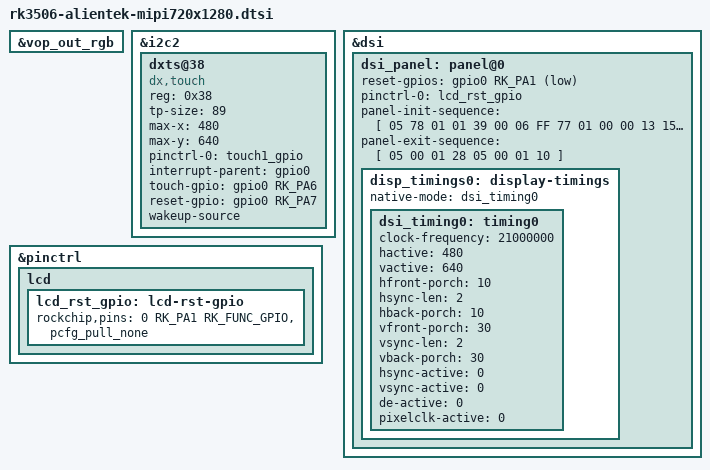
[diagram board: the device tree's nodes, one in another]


#define D310T9362V1     0
#define D350T1013V1     0
#define D240C2501V1     1	
#define D280C2518V0     0	
#define D300T9307V1     0
#define D200C2409V0     0
#define D500C9366V1     0 
#define D395C930UV0     0
#define D500C930SV0     0   //5" g5 7201280
#define D050C2523V0     0   //5" g6 7201280
#define D050C2521V0     0   //5" 1024600
#define D070C2529V0     0    //7" 1024600
#define D060C2522V0     0   //6" 720 1440
#define D320C2403V1     0
#define D200N2415V0     0









&vop_out_rgb {
        /delete-property/ remote-endpoint;
};



&i2c2 {





	dxts@38 {

               compatible = "dx,touch";
               reg = <0x38>;
               tp-size = <89>;
               max-x = <480>;
               max-y = <640>;
               pinctrl-names = "default";
               pinctrl-0 = <&touch1_gpio>;
	       interrupt-parent = <&gpio0>;
               touch-gpio = <&gpio0 RK_PA6 IRQ_TYPE_LEVEL_LOW>;
               reset-gpio = <&gpio0 RK_PA7 GPIO_ACTIVE_HIGH>;
                wakeup-source;
                //touchscreen-inverted-x;
                //touchscreen-swapped-x-y;
                status = "okay";
        };

	/delete-node/ gt1x;
};






// ************************************************************************************************************************************************
// 3.1寸大显 D310T9362V1
// 480x800
// ************************************************************************************************************************************************
	#if(D310T9362V1)
	

&dsi {
	status = "okay";
//	rockchip,lane-rate = <1000>;
        dsi_panel: panel@0 {
        	reset-gpios = <&gpio0 RK_PA1 GPIO_ACTIVE_LOW>;
                pinctrl-names = "default";
                pinctrl-0 = <&lcd_rst_gpio>;

		panel-init-sequence = [
			// init code
			05 78 01 01
			05 78 01 11
			39 00 06 FF 77 01 00 00 11
			15 00 02 D1 11
			15 00 02 55 B0 // 80 90 b0
			39 00 06 FF 77 01 00 00 10
			39 00 03 C0 63 00
			39 00 03 C1 09 02
			39 00 03 C2 37 08
			15 00 02 C7 00 // x-dir rotate 0:0x00,rotate 180:0x04
			15 00 02 CC 38
			39 00 11 B0 00 11 19 0C 10 06 07 0A 09 22 04 10 0E 28 30 1C
			39 00 11 B1 00 12 19 0D 10 04 06 07 08 23 04 12 11 28 30 1C
			39 00 06 FF 77 01 00 00 11 // enable  bk fun of  command 2  BK1
			15 00 02 B0 4D
			15 00 02 B1 60 // 0x56  0x4a  0x5b
			15 00 02 B2 07
			15 00 02 B3 80
			15 00 02 B5 47
			15 00 02 B7 8A
			15 00 02 B8 21
			15 00 02 C1 78
			15 00 02 C2 78
			15 64 02 D0 88
			39 00 04 E0 00 00 02
			39 00 0C E1 01 A0 03 A0 02 A0 04 A0 00 44 44
			39 00 0D E2 00 00 00 00 00 00 00 00 00 00 00 00
			39 00 05 E3 00 00 33 33
			39 00 03 E4 44 44
			39 00 11 E5 01 26 A0 A0 03 28 A0 A0 05 2A A0 A0 07 2C A0 A0
			39 00 05 E6 00 00 33 33
			39 00 03 E7 44 44
			39 00 11 E8 02 26 A0 A0 04 28 A0 A0 06 2A A0 A0 08 2C A0 A0
			39 00 08 EB 00 01 E4 E4 44 00 40
			39 00 11 ED FF F7 65 4F 0B A1 CF FF FF FC 1A B0 F4 56 7F FF
		  //  39 00 06 FF 77 01 00 00 12  //BIST
          //  15 00 02 D1 81 
		  //  15 00 02 D2 07
			39 00 06 FF 77 01 00 00 00
			15 00 02 36 00 //U&D  Y-DIR rotate 0:0x00,rotate 180:0x10
			05 78 01 11           
			05 14 01 29		
		];

		panel-exit-sequence = [
			05 00 01 28
			05 00 01 10
		];

                disp_timings0: display-timings {
                        native-mode = <&dsi_timing0>;
                        dsi_timing0: timing0 {
 				clock-frequency = <27000000>;
				hactive = <480>;   	
				vactive = <800>;   	 
				hfront-porch = <32>;  
				hsync-len = <4>;   	 
				hback-porch = <32>;  
				vfront-porch = <9>;  
				vsync-len = <4>;     
				vback-porch = <3>;   
				hsync-active = <0>;
				vsync-active = <0>;
				de-active = <0>;
				pixelclk-active = <0>;
                        };
                };

        };
};
#endif






// ************************************************************************************************************************************************
// 3.5寸大显 D350T1013V1
// 480x800
// ************************************************************************************************************************************************
	#if(D350T1013V1)
	
&dsi {
	status = "okay";
//	rockchip,lane-rate = <1000>;
        dsi_panel: panel@0 {
        	reset-gpios = <&gpio0 RK_PA1 GPIO_ACTIVE_LOW>;
                pinctrl-names = "default";
                pinctrl-0 = <&lcd_rst_gpio>;

		panel-init-sequence = [
			// init code
			05 78 01 01
			39 00 06 FF 77 01 00 00 13
			15 00 02 EF 08
			39 00 06 FF 77 01 00 00 10
			39 00 03 C0 63 00
			39 00 03 C1 10 02
			39 00 03 C2 31 02
			15 00 02 CC 10
			39 00 11 B0 C0 0C 92 0C 10 05 02 0D 07 21 04 53 11 6A 32 1F
			39 00 11 B1 C0 87 CF 0C 10 06 00 03 08 1D 06 54 12 E6 EC 0F
			39 00 06 FF 77 01 00 00 11 //  BK1
			15 00 02 B0 5D
			15 00 02 B1 72 // VCOM
			15 00 02 B2 82
			15 00 02 B3 80
			15 00 02 B5 42
			15 00 02 B7 85
			15 00 02 B8 20
			15 00 02 C1 78
			15 00 02 C2 78
			15 64 02 D0 88
			39 00 04 E0 00 00 02
			39 00 0C E1 04 A0 06 A0 05 A0 07 A0 00 44 44
			39 00 0D E2 00 00 33 33 01 A0 00 00 01 A0 00 00
			39 00 05 E3 00 00 33 33
			39 00 03 E4 44 44
			39 00 11 E5 0C 30 A0 A0 0E 32 A0 A0 08 2C A0 A0 0A 2E A0 A0
			39 00 05 E6 00 00 33 33
			39 00 03 E7 44 44
			39 00 11 E8 0D 31 A0 A0 0F 33 A0 A0 09 2D A0 A0 0B 2F A0 A0
			39 00 08 EB 00 01 E4 E4 44 88 00
			39 00 11 ED FF F5 47 6F 0B A1 A2 BF FB 2A 1A B0 F6 74 5F FF
			39 00 07 FF 08 08 08 40 3F 64
			39 00 06 FF 77 01 00 00 13
			39 00 03 E8 00 0E
			39 00 06 FF 77 01 00 00 00
			05 78 01 11    
			39 00 06 FF 77 01 00 00 13
			39 14 03 E8 00 0C   
			39 00 03 E8 00 00  
          //  39 00 06 FF 77 01 00 00 12  //BIST
          //  15 00 D1 81 
		  //  15 00 D2 07
			39 00 06 FF 77 01 00 00 00 
			05 14 01 29		
		];

		panel-exit-sequence = [
			05 00 01 28
			05 00 01 10
		];

                disp_timings0: display-timings {
                        native-mode = <&dsi_timing0>;
                        dsi_timing0: timing0 {
 				clock-frequency = <27000000>;
				hactive = <480>;   	
				vactive = <800>;   	 
				hfront-porch = <32>;  
				hsync-len = <4>;   	 
				hback-porch = <32>;  
				vfront-porch = <9>;  
				vsync-len = <4>;     
				vback-porch = <3>;   
				hsync-active = <0>;
				vsync-active = <0>;
				de-active = <0>;
				pixelclk-active = <0>;
                        };
                };

        };
};
#endif


// ************************************************************************************************************************************************
// 2.4寸大显 D240C2501V1
// 480x640
// ************************************************************************************************************************************************
 
	#if(D240C2501V1)
&dsi {
	status = "okay";
//	rockchip,lane-rate = <1000>;
        dsi_panel: panel@0 {
        	reset-gpios = <&gpio0 RK_PA1 GPIO_ACTIVE_LOW>;
                pinctrl-names = "default";
                pinctrl-0 = <&lcd_rst_gpio>;

		panel-init-sequence = [
			// init code
			05 78 01 01
			39 00 06 FF 77 01 00 00 13
			15 00 02 EF 08
			39 00 06 FF 77 01 00 00 10
			39 00 03 C0 4F 00
			39 00 03 C1 10 0C
			39 00 03 C2 37 04
			15 00 02 C7 00 // x-dir rotate 0:0x00,rotate 180:0x04
			15 00 02 CC 10
			39 00 11 B0 00 0B 13 0D 10 07 02 08 07 1F 04 11 0F 28 2F 1F
			39 00 11 B1 00 0C 13 0C 10 05 02 08 08 1E 05 13 11 27 30 1F
			39 00 06 FF 77 01 00 00 11 // enable  bk fun of  command 2  BK1
			15 00 02 B0 4A //VOP
			15 00 02 B1 4A // VCOM
			15 00 02 B2 87 //VGH
			15 00 02 B3 80
			15 00 02 B5 45 //VGL
			15 00 02 B7 85
			15 00 02 B8 20
			15 00 02 C1 78
			15 00 02 C2 78
			15 64 02 D0 88
			39 00 04 E0 00 00 02
			39 00 0C E1 04 B0 06 B0 05 B0 05 B0 00 44 44
			39 00 0D E2 20 20 44 44 96 A0 00 00 96 A0 00 00
			39 00 05 E3 00 00 22 22
			39 00 03 E4 44 44
			39 00 11 E5 0C 90 B0 A0 0E 92 B0 A0 08 8C B0 A0 0A 8E B0 A0
			39 00 05 E6 00 00 22 22
			39 00 03 E7 44 44
			39 00 11 E8 0D 91 B0 A0 0F 93 B0 A0 09 8D B0 A0 0B 8F B0 A0
			39 00 03 E9 36 44
			39 00 08 EB 00 00 E4 E4 44 00 40
			39 00 11 ED C1 A2 BF 0F 67 45 FF FF FF FF 54 76 F0 FB 2A 1C
			39 00 07 EF 10 0D 04 08 3F 1F
			39 00 06 FF 77 01 00 00 13
		    39 00 03 E8 00 0E
			39 00 06 FF 77 01 00 00 00
	        05 78 01 11
			39 00 06 FF 77 01 00 00 13
		    39 14 03 E8 00 0C
		    39 14 03 E8 00 00
			39 00 06 FF 77 01 00 00 00
			15 00 02 36 00 //U&D  Y-DIR rotate 0:0x00,rotate 180:0x10          
			05 14 01 29		
		];

		panel-exit-sequence = [
			05 00 01 28
			05 00 01 10
		];

                disp_timings0: display-timings {
                        native-mode = <&dsi_timing0>;
                        dsi_timing0: timing0 {
				clock-frequency = <21000000>;
				hactive = <480>;   	
				vactive = <640>;   	 
				hfront-porch = <10>;  
				hsync-len = <2>;   	 
				hback-porch = <10>;  
				vfront-porch = <30>;  
				vsync-len = <2>;     
				vback-porch = <30>;   
				hsync-active = <0>;
				vsync-active = <0>;
				de-active = <0>;
				pixelclk-active = <0>;
                        };
                };

        };
};
#endif



// ************************************************************************************************************************************************
// 2.8寸大显 D280C2518V0
// 480x640
// ************************************************************************************************************************************************
 	#if(D280C2518V0)
	
&dsi {
	status = "okay";
//	rockchip,lane-rate = <1000>;
        dsi_panel: panel@0 {
        	reset-gpios = <&gpio0 RK_PA1 GPIO_ACTIVE_LOW>;
                pinctrl-names = "default";
                pinctrl-0 = <&lcd_rst_gpio>;

		panel-init-sequence = [
			// init code
39 00 06 FF 77 01 00 00 13
15 00 02 EF 08
39 00 06 FF 77 01 00 00 10
39 00 03 C0 4F 00
39 00 03 C1 10 02
39 00 03 C2 00 02
15 00 02 CC 10
39 00 11 B0 00 10 17 0D 11 06 05 08 07 1F 04 11 0E 29 30 1F
39 00 11 B1 00 0D 14 0E 11 06 04 08 08 20 05 13 13 26 30 1F
39 00 06 FF 77 01 00 00 11
15 00 02 B0 69
15 00 02 B1 71
15 00 02 B2 82
15 00 02 B3 80
15 00 02 B5 42
15 00 02 B7 85
15 00 02 B8 20
15 00 02 C0 09
15 00 02 C1 78
15 00 02 C2 78
15 00 02 D0 88
15 00 02 EE 42
39 00 04 E0 00 00 02
39 00 0c E1 04 A0 06 A0 05 A0 07 A0 00 44 44
39 00 0d E2 00 00 00 00 00 00 00 00 00 00 00 00
39 00 05 E3 00 00 22 22
39 00 03 E4 44 44
39 00 11 E5 0c 90 A0 A0 0E 92 A0 A0 08 8C A0 A0 0A 8E A0 A0
39 00 05 E6 00 00 22 22
39 00 03 E7 44 44
39 00 11 E8 0D 91 A0 A0 0F 93 A0 A0 09 8D A0 A0 0B 8F A0 A0
//39 00 03 E9 36 00
39 00 08 EB 00 00 E4 E4 44 00 40
39 00 11 ED FF F5 47 6F 0B A1 AB FF FF BA 1A B0 F6 74 5F FF
39 00 07 EF 08 08 08 40 3F 64
39 00 06 FF 77 01 00 00 00
39 00 06 FF 77 01 00 00 13
39 00 03 E6 16 7C
39 00 03 E8 00 0E
39 00 06 FF 77 01 00 00 00
15 78 02 11 00
39 00 06 FF 77 01 00 00 13
39 14 03 E8 00 0C
39 00 03 E8 00 00
//bist
//39 00 06 FF 77 01 00 00 12
//15 00 02 D1 81
//15 00 02 D2 07
39 00 06 FF 77 01 00 00 00
15 00 02 3A 70
05 14 01 29
		];

		panel-exit-sequence = [
			05 00 01 28
			05 00 01 10
		];

                disp_timings0: display-timings {
                        native-mode = <&dsi_timing0>;
                        dsi_timing0: timing0 {
				clock-frequency = <21000000>;
				hactive = <480>;   	
				vactive = <640>;   	 
				hfront-porch = <10>;  
				hsync-len = <2>;   	 
				hback-porch = <10>;  
				vfront-porch = <30>;  
				vsync-len = <2>;     
				vback-porch = <30>;   
				hsync-active = <0>;
				vsync-active = <0>;
				de-active = <0>;
				pixelclk-active = <0>;
                        };
                };

        };
};
#endif




// ************************************************************************************************************************************************
// 3.0寸大显 D300T9307V1
// 480x854
// ************************************************************************************************************************************************
	#if(D300T9307V1)
	
&dsi {
	status = "okay";
        dsi_panel: panel@0 {
        	reset-gpios = <&gpio0 RK_PA1 GPIO_ACTIVE_LOW>;
                pinctrl-names = "default";
                pinctrl-0 = <&lcd_rst_gpio>;

		panel-init-sequence = [
			// init code
			15 00 02 B0 5D
			15 00 02 B1 72 // VCOM
			15 00 02 B2 82
			15 00 02 B3 80
			15 00 02 B5 42
			15 00 02 B7 85
		05 78 01 01
			39 00 06 FF 77 01 00 00 13
			15 00 02 EF 08
			39 00 06 FF 77 01 00 00 10
			39 00 03 C0 E9 03
			39 00 03 C1 12 0C
			39 00 03 C2 27 0A
			15 00 02 CC 10
			39 00 11 B0 00 23 2A 0A 0E 03 12 06 06 2A 00 10 0F 2D 34 1F
			39 00 11 B1 00 24 2B 0F 12 07 15 0A 0A 2B 08 13 10 2D 33 1F
			39 00 06 FF 77 01 00 00 11 // enable  bk fun of  command 2  BK1
			15 00 02 B0 5D
			15 00 02 B1 74 // VCOM
			15 00 02 B2 84
			15 00 02 B3 80
			15 00 02 B5 45
			15 00 02 B7 85
			15 00 02 B8 33
			15 00 02 C1 78
			15 00 02 C2 78
			15 64 02 D0 88
			39 00 04 E0 00 00 02
            39 00 0C E1 06 A0 08 A0 05 A0 07 A0 00 44 44 
            39 00 0D E2 30 30 44 44 6E A0 00 00 6E A0 00 00 
            39 00 05 E3 00 00 33 33 
            39 00 03 E4 44 44 
            39 00 11 E5 0D 69 0A A0 0F 6B 0A A0 09 65 0A A0 0B 67 0A A0 
            39 00 05 E6 00 00 33 33 
            39 00 03 E7 44 44 
            39 00 11 E8 0C 68 0A A0 0E 6A 0A A0 08 64 0A A0 0A 66 0A A0 
            39 00 03 E9 36 00 
            39 00 08 EB 00 01 E4 E4 44 88 40 
            39 00 11 ED FF 45 67 FA 01 2B CF FF FF FC B2 10 AF 76 54 FF  
            39 00 07 EF 10 0D 04 08 3F 1F 
            //BIST
            //39 00 06 FF 77 01 00 00 12
            //15 00 02 D1 81
             //15 00 02 D2 07
			39 00 06 FF 77 01 00 00 00
			15 00 02 36 00 
			15 00 02 3A 70
			05 78 01 11           
			05 14 01 29		
		];

		panel-exit-sequence = [
			05 00 01 28
			05 00 01 10
		];

                disp_timings0: display-timings {
                        native-mode = <&dsi_timing0>;
                        dsi_timing0: timing0 {
 				clock-frequency = <27000000>;
				hactive = <480>;   	
				vactive = <854>;   	 
				hfront-porch = <7>;  
				hsync-len = <2>;   	 
				hback-porch = <11>;  
				vfront-porch = <22>;  
				vsync-len = <2>;     
				vback-porch = <12>;   
				hsync-active = <0>;
				vsync-active = <0>;
				de-active = <0>;
				pixelclk-active = <0>;
                        };
                };

        };
};
#endif







&pinctrl {
        lcd {
                lcd_rst_gpio: lcd-rst-gpio {
                        rockchip,pins = <0 RK_PA1 RK_FUNC_GPIO &pcfg_pull_none>;
                };
        };
};



// ************************************************************************************************************************************************
// 2.0寸大显 D200C2409V0
// 480x640
// ************************************************************************************************************************************************
 	#if(D200C2409V0)
	
&dsi {
	status = "okay";
        dsi_panel: panel@0 {
        	reset-gpios = <&gpio0 RK_PA1 GPIO_ACTIVE_LOW>;
                pinctrl-names = "default";
                pinctrl-0 = <&lcd_rst_gpio>;

		panel-init-sequence = [
			// init code
  05 78 01 01
  39 00 06 FF 77 01 00 00 13  
  15 00 02 EF 08 	 
  39 00 06 FF 77 01 00 00 10 
  39 00 03 C0 4F 00 
  39 00 03 C1 11 0C 
  39 00 03 C2 07 0A 
  39 00 04 C3 83 33 1b  		
  15 00 02 CC 10 
  39 00 11 B0 00 0F 18 0D 12 07 05 08 07 21 03 10 0F 26 2F 1F 
  39 00 11 B1 00 1B 20 0C 0E 03 08 08 08 22 05 11 0F 2A 32 1F 
  39 00 06 FF 77 01 00 00 11 
  15 00 02 B0 35 
  15 00 02 B1 6a 
  15 00 02 B2 81 
  15 00 02 B3 80 
  15 00 02 B5 4E 
  15 00 02 B7 85 
  15 00 02 B8 21 
  15 00 02 C0 09 
  15 00 02 C1 78 
  15 00 02 C2 78 
  15 00 02 D0 88 
  39 00 04 E0 00 A0 02 
  39 00 0C E1 06 A0 08 A0 05 A0 07 A0 00 44 44 
  39 00 0E E2 20 20 40 40 96 A0 00 00 96 A0 00 00 00 
  39 00 05 E3 00 00 22 22 
  39 00 03 E4 44 44 
  39 00 11 E5 0E 97 10 A0 10 99 10 A0 0A 93 10 A0 0C 95 10 A0 
  39 00 05 E6 00 00 22 22 
  39 00 03 E7 44 44 
  39 00 11 E8 0D 96 10 A0 0F 98 10 A0 09 92 10 A0 0B 94 10 A0 
  39 00 08 EB 00 01 4E 4E 44 88 40 
  39 00 03 EC 78 00 
  39 00 11 ED FF FA 2F 89 76 54 01 FF FF 10 45 67 98 F2 AF FF 
  39 00 07 EF 08 08 08 45 3F 54 
  39 00 06 FF 77 01 00 00 13 
  39 00 03 E8 00 0E 
  39 14 03 E8 00 0C 
  39 00 03 E8 00 00 
  39 00 06 FF 77 01 00 00 00 
  05 78 01 11
  15 00 02 3A 70  
  05 14 01 29
		];

		panel-exit-sequence = [
			05 00 01 28
			05 00 01 10
		];

                disp_timings0: display-timings {
                        native-mode = <&dsi_timing0>;
                        dsi_timing0: timing0 {
				clock-frequency = <21000000>;
				hactive = <480>;   	
				vactive = <640>;   	 
				hfront-porch = <10>;  
				hsync-len = <2>;   	 
				hback-porch = <10>;  
				vfront-porch = <30>;  
				vsync-len = <2>;     
				vback-porch = <30>;   
				hsync-active = <0>;
				vsync-active = <0>;
				de-active = <0>;
				pixelclk-active = <0>;
                        };
                };

        };
};
#endif



// ************************************************************************************************************************************************
// 5.0寸大显 D500C930SV0
// 720x1280
// ************************************************************************************************************************************************
 	#if(D500C930SV0)
	
&dsi {
	status = "okay";
        dsi_panel: panel@0 {
        	reset-gpios = <&gpio0 RK_PA1 GPIO_ACTIVE_LOW>;
                pinctrl-names = "default";
                pinctrl-0 = <&lcd_rst_gpio>;

		panel-init-sequence = [

  39 00 04 B9 F1 12 83 
  39 00 04 B2 C8 12 30 
  39 00 0B B3 10 10 28 28 03 FF 00 00 00 00 
  15 00 02 B4 80 
  39 00 03 B5 0A 0A 
  39 00 03 B6 50 50
  39 00 05 B8 26 22 F0 63
  39 00 1C BA 31 81 05 F9 0E 0E 20 00 00 00 00 00 00 00 44 25 00 90 0A 00 00 01 4F 01 00 00 37 
  15 00 02 BC 46
  39 00 04 BF 02 11 00
  39 00 0A C0 73 73 50 50 00 00 12 50 00 
  39 00 0D C1 26 00 32 32 77 E4 DD DD 77 77 33 33
  15 00 02 CC 0B 
  39 00 23 E0 08 09 09 30 30 3F 2D 28 05 09 0C 10 12 10 12 0F 18 00 09 09 30 30 3F 2D 28 05 09 0C 10 12 10 12 0F 18 
  39 00 0F E3 03 03 03 03 00 03 00 00 00 00 FF 80 C0 10                     
  39 00 40 E9 C8 10 0C 00 00 80 81 12 31 23 4F 8A 80 81 47 20 00 00 30 00 00 00 00 00 30 00 00 00 02 46 02 88 88 88 88 88 88 88 F8 13 57 13 88 88 88 88 88 88 88 F8 00 00 00 01 00 00 00 00 00 00 00 00 00 
  39 00 3E EA 00 1A 00 00 00 00 02 00 00 00 00 00 75 31 31 88 88 88 88 88 88 88 8F 64 20 20 88 88 88 88 88 88 88 8F 23 20 00 00 88 00 00 00 00 00 00 00 00 00 00 00 00 00 00 00 00 00 00 00 00 00 00 
  05 78 01 11
  05 14 01 29 
  ];
  		panel-exit-sequence = [
			05 00 01 28
			05 00 01 10
		];

                disp_timings0: display-timings {
                        native-mode = <&dsi_timing0>;
                        dsi_timing0: timing0 {
		clock-frequency = <67000000>;
				hactive = <720>;   	
				vactive = <1280>;   	 
				hfront-porch = <48>;  
				hsync-len = <12>;   	 
				hback-porch = <43>;  

				vfront-porch = <8>;  
				vsync-len = <12>;     
				vback-porch = <28>; 
				hsync-active = <0>;
				vsync-active = <0>;
				de-active = <0>;
				pixelclk-active = <0>;
                        };
                };

        };
};
#endif




// ************************************************************************************************************************************************
// 3.2寸大显 D320C2403V1
// 1024x768
// ************************************************************************************************************************************************
 	#if(D320C2403V1)
	
&dsi {
	status = "okay";
        dsi_panel: panel@0 {
        	reset-gpios = <&gpio0 RK_PA1 GPIO_ACTIVE_LOW>;
                pinctrl-names = "default";
                pinctrl-0 = <&lcd_rst_gpio>;

		panel-init-sequence = [

39 00 04 df 91 68 f9
15 00 02 de 00
//15 00 02 C2 30  //bist
39 00 03 b2 00 7e
39 00 03 b3 00 7e
39 00 07 c1 00 10 00 00 00 00
39 00 08 bb 02 24 07 61 19 44 44
39 00 03 be 1a f2
39 00 0f c3 10 17 5a 17 5a 05 05 05 05 15 15 31 05 df
39 00 08 c4 11 80 00 df 09 06 14
15 00 02 cc 35  //2lane
39 00 18 ce 00 03 03 03 03 03 03 03 03 03 03 03 03 03 03 03 03 03 03 03 03 0f 03
39 00 0a cf 00 01 40 01 ca 01 ca 01 ca
39 00 18 d0 00 1f 1f 1f 1f 1f 1f 1f 1f 1f 1f 03 01 05 07 09 0b 1e 15 1f 1f 15 1f
39 00 18 d1 00 1f 1f 1f 1f 1f 1f 1f 1f 1f 1f 02 00 04 06 08 0a 1e 15 1f 1f 15 1f
39 00 18 d2 00 1f 1f 1f 1f 1f 1f 1f 1f 1f 1f 00 02 0a 08 06 04 1f 15 1f 1f 15 1e
39 00 18 d3 00 1f 1f 1f 1f 1f 1f 1f 1f 1f 1f 01 03 0b 09 07 05 1f 15 1f 1f 15 1e
39 00 26 d4 30 00 00 04 00 06 00 00 00 00 00 03 03 00 11 00 01 c0 04 01 01 11 80 01 c0 05 01 01 00 00 00 04 00 06 18 02 e3
39 00 09 d5 68 73 00 08 08 00 03 00
39 00 07 b7 00 d8 00 00 d8 00
39 00 27 c8 7f 69 5a 4e 4a 3b 40 2a 44 43 44 63 51 59 4c 48 3a 28 0f 7f 69 5a 4e 4a 3b 40 2a 44 43 44 63 51 59 4c 48 3a 28 0f
15 00 02 de 02
39 00 05 bb 00 5b 5c 41
39 00 04 b5 00 5a 0a
15 00 02 c6 22
15 00 02 d7 12
39 00 03 E7 00 00
15 00 02 DE 04
15 00 02 CC 02
15 00 02 E7 01
15 00 02 DE 00
15 00 02 35 00
05 78 01 11
05 14 01 29
  ];
  		panel-exit-sequence = [
			05 00 01 28
			05 00 01 10
		];

                disp_timings0: display-timings {
                        native-mode = <&dsi_timing0>;
                        dsi_timing0: timing0 {
				clock-frequency = <50000000>;
				hactive = <1024>;   	
				vactive = <768>;   	 
				hfront-porch = <10>;  
				hsync-len = <2>;   	 
				hback-porch = <10>;  
				vfront-porch = <6>;  
				vsync-len = <2>;     
				vback-porch = <20>;   
				hsync-active = <0>;
				vsync-active = <0>;
				de-active = <0>;
				pixelclk-active = <0>;
                        };
                };

        };
};
#endif


